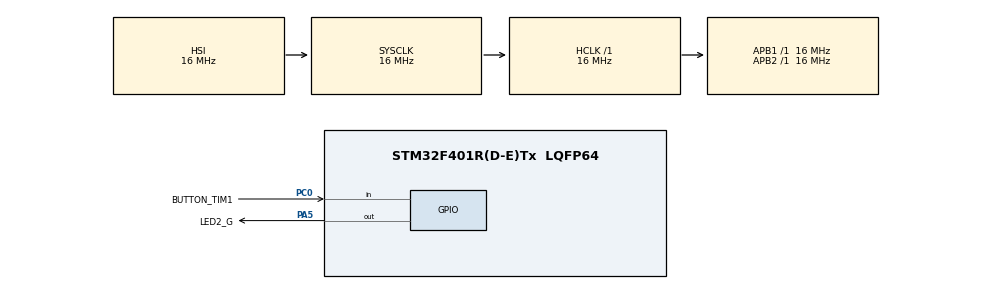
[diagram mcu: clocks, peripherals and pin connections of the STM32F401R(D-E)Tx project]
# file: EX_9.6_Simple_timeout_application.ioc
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Mcu.Family=STM32F4
RCC.CortexFreq_Value=16000000
PC0.GPIO_Label=BUTTON_TIM1
PC0.Signal=GPIO_Input
ProjectManager.StackSize=0x400
PA13.Signal=SYS_JTMS-SWDIO
TIM1.Prescaler=999
ProjectManager.TargetToolchain=STM32CubeIDE
RCC.LSE_VALUE=32768
RCC.AHBFreq_Value=16000000
PA5.Signal=GPIO_Output
RCC.HSE_VALUE=25000000
board=custom
RCC.VCOOutputFreq_Value=192000000
RCC.APB2Freq_Value=16000000
PA14.Mode=Serial_Wire
PA13.Mode=Serial_Wire
Mcu.Name=STM32F401R(D-E)Tx
VP_TIM1_VS_ClockSourceINT.Mode=Internal
RCC.SYSCLKFreq_VALUE=16000000
Mcu.Package=LQFP64
PA5.GPIO_Label=LED2_G
PA14.Signal=SYS_JTCK-SWCLK
ProjectManager.HeapSize=0x200
NVIC.TIM1_UP_TIM10_IRQn=true\:0\:0\:false\:false\:true\:true\:true
RCC.HSI_VALUE=16000000
NVIC.PriorityGroup=NVIC_PRIORITYGROUP_4
TIM1.Period=31999
PC0.GPIO_PuPd=GPIO_PULLUP
RCC.APB1Freq_Value=16000000

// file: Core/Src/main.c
/* USER CODE BEGIN Header */
/**
 * -The code should toggle a led.
	-The toggle function should be in the update timer interrupt handler(ISR).
	-A button starts the Timer and after two seconds the update interrupt is triggered.
	-The timer should stop and wait until we press the button then the timer starts again.
 *
  ******************************************************************************
  * @file           : main.c
  * @brief          : Main program body
  ******************************************************************************
  * @attention
  *
  * <h2><center>&copy; Copyright (c) 2021 STMicroelectronics.
  * All rights reserved.</center></h2>
  *
  * This software component is licensed by ST under BSD 3-Clause license,
  * the "License"; You may not use this file except in compliance with the
  * License. You may obtain a copy of the License at:
  *                        opensource.org/licenses/BSD-3-Clause
  *
  ******************************************************************************
  */
/* USER CODE END Header */
#include "main.h"
#include "tim.h"
#include "gpio.h"

void SystemClock_Config(void);

/* USER CODE BEGIN 0 */

//Function to toggle the led
//This Function is called when an overflow occurs(after 2 seconds in TIM1)
void HAL_TIM_PeriodElapsedCallback(TIM_HandleTypeDef *htim)
{
	//Stop the TIM1
	HAL_TIM_Base_Stop_IT(&htim1);
	//Counter of the TIM1 becomes to 0
	__HAL_TIM_SET_COUNTER(&htim1,0);
	//toggle the led green
	HAL_GPIO_TogglePin(LED2_G_GPIO_Port, LED2_G_Pin);

}

/* USER CODE END 0 */

int main(void)
{

  /* MCU Configuration--------------------------------------------------------*/

  /* Reset of all peripherals, Initializes the Flash interface and the Systick. */
  HAL_Init();

  /* Configure the system clock */
  SystemClock_Config();

  /* Initialize all configured peripherals */
  MX_GPIO_Init();
  MX_TIM1_Init();
  /* USER CODE BEGIN 2 */
  //This function helps us to deactivate the update flag and so the interrupt doesn't happen when
  // we press the button for the first time and the code is beginning
  //Without instruction here in this place, we press the button and toggle the led without waiting 2 seconds
  // this is because the flag is true(non-zero).
  __HAL_TIM_CLEAR_FLAG(&htim1,TIM_FLAG_UPDATE);

  /* USER CODE END 2 */

  /* Infinite loop */
  while (1)
  {
	  //Conditional to check if the button was pressed
	  //Note: PC0 is in mode pull-up
	  if (HAL_GPIO_ReadPin(BUTTON_TIM1_GPIO_Port, BUTTON_TIM1_Pin) == GPIO_PIN_RESET)
	  {
		  //start TIM1 base and enable the interruption
		  HAL_TIM_Base_Start_IT(&htim1);

	  }

  }
}

void SystemClock_Config(void)
{
  RCC_OscInitTypeDef RCC_OscInitStruct = {0};
  RCC_ClkInitTypeDef RCC_ClkInitStruct = {0};

  /** Configure the main internal regulator output voltage
  */
  __HAL_RCC_PWR_CLK_ENABLE();
  __HAL_PWR_VOLTAGESCALING_CONFIG(PWR_REGULATOR_VOLTAGE_SCALE2);
  /** Initializes the RCC Oscillators according to the specified parameters
  * in the RCC_OscInitTypeDef structure.
  */
  RCC_OscInitStruct.OscillatorType = RCC_OSCILLATORTYPE_HSI;
  RCC_OscInitStruct.HSIState = RCC_HSI_ON;
  RCC_OscInitStruct.HSICalibrationValue = RCC_HSICALIBRATION_DEFAULT;
  RCC_OscInitStruct.PLL.PLLState = RCC_PLL_NONE;
  if (HAL_RCC_OscConfig(&RCC_OscInitStruct) != HAL_OK)
  {
    Error_Handler();
  }
  /** Initializes the CPU, AHB and APB buses clocks
  */
  RCC_ClkInitStruct.ClockType = RCC_CLOCKTYPE_HCLK|RCC_CLOCKTYPE_SYSCLK
                              |RCC_CLOCKTYPE_PCLK1|RCC_CLOCKTYPE_PCLK2;
  RCC_ClkInitStruct.SYSCLKSource = RCC_SYSCLKSOURCE_HSI;
  RCC_ClkInitStruct.AHBCLKDivider = RCC_SYSCLK_DIV1;
  RCC_ClkInitStruct.APB1CLKDivider = RCC_HCLK_DIV1;
  RCC_ClkInitStruct.APB2CLKDivider = RCC_HCLK_DIV1;

  if (HAL_RCC_ClockConfig(&RCC_ClkInitStruct, FLASH_LATENCY_0) != HAL_OK)
  {
    Error_Handler();
  }
}

void Error_Handler(void)
{
  __disable_irq();
  while (1)
  {
  }
}

/************************ (C) COPYRIGHT STMicroelectronics *****END OF FILE****/
